# AT32M416xx_v2 register map
Vendor: Keil; Series: AT32M416; File version: 1.0
CPU: CM4 r0p1, little endian, no MPU, FPU, 4 interrupt priority bits
Registers are 32-bit, read-write, reset 0x0 unless marked. A register's access mark holds for its fields unless they carry their own. Offsets are from the block's base; [hi:lo] are bit positions.

## DAC — Digital to analog converter
Base 0x40007400
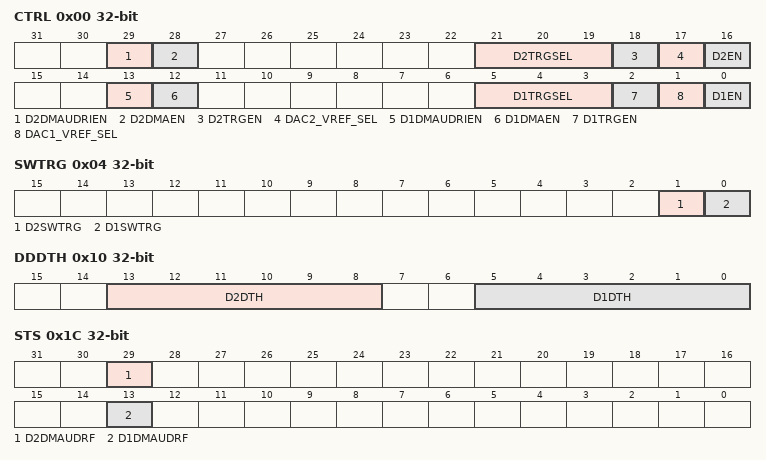
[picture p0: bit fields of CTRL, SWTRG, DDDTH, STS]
0x00 CTRL — Control register (DAC_CTRL)
  [29] D2DMAUDRIEN — DAC2 DMA underrun interrupt enable
  [28] D2DMAEN — DAC2 DMA enable
  [21:19] D2TRGSEL — DAC2 trigger selection
  [18] D2TRGEN — DAC2 trigger enable
  [17] DAC2_VREF_SEL — DAC2 reference voltage switch
  [16] D2EN — DAC2 enable
  [13] D1DMAUDRIEN — DAC1 DMA underrun interrupt enable
  [12] D1DMAEN — DAC1 DMA enable
  [5:3] D1TRGSEL — DAC1 trigger selection
  [2] D1TRGEN — DAC1 trigger enable
  [1] DAC1_VREF_SEL — DAC1 reference voltage switch
  [0] D1EN — DAC1 enable
0x04 SWTRG wo — DAC software trigger register(DAC_SWTRIGR)
  [1] D2SWTRG — DAC2 software trigger
  [0] D1SWTRG — DAC1 software trigger
0x08 D1DTH — DAC1 6-bit right-aligned data holding register(DAC_D1DTH)
  [5:0] D1DTH — DAC1 6-bit right-aligned data
0x0C D2DTH — DAC2 6-bit right aligned data holding register (DAC_D2DTH)
  [5:0] D2DTH — DAC2 6-bit right-aligned data
0x10 DDDTH — Dual DAC 6-bit right-aligned data holding register (DAC_DDDTH), Bits 31:14 Reserved, Bits 7:6 Reserved
  [13:8] D2DTH — DAC2 6-bit right-aligned data
  [5:0] D1DTH — DAC1 6-bit right-aligned data
0x14 D1ODT ro — DAC1 data output register (DAC_D1ODT)
  [5:0] D1ODT — DAC1 data output
0x18 D2ODT ro — DAC2 data output register (DAC_D2ODT)
  [5:0] D2ODT — DAC2 data output
0x1C STS — DAC status register(DAC_STS)
  [29] D2DMAUDRF — DAC2 DMA underrun flag
  [13] D1DMAUDRF — DAC1 DMA underrun flag
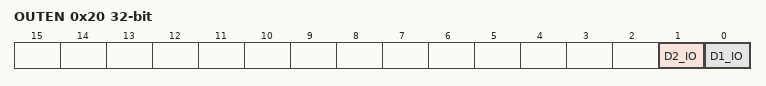
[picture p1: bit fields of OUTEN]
0x20 OUTEN — DAC output enable register(DAC_OUTEN)
  [1] D2_IO — DAC2 output to GPIO
  [0] D1_IO — DAC1 output to GPIO

## CMP — Comparator
Base 0x40013830
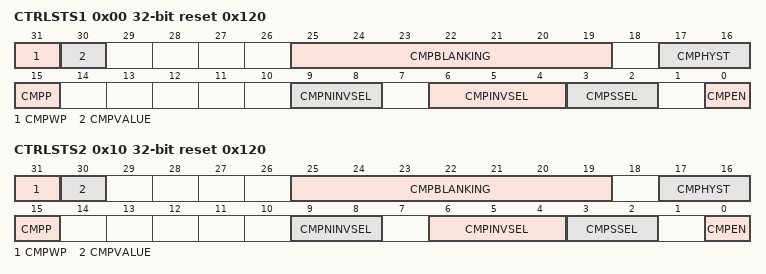
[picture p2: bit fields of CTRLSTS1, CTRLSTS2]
0x00 CTRLSTS1 reset 0x120 — CMP1 control and status register (CMP1_CTRLSTS)
  [31] CMPWP — Comparator write protect
  [30] CMPVALUE — Comparator 1 output value
  [25:19] CMPBLANKING — Comparator blank source
  [17:16] CMPHYST — Comparator hysteresis
  [15] CMPP — Comparator polarity
  [9:8] CMPNINVSEL — Comparator non-inverting selection
  [6:4] CMPINVSEL — Comparator inverting selection
  [3:2] CMPSSEL — Comparator speed selection
  [0] CMPEN — Comparator enable
0x04 G_FILTER_EN_1 — CMP1 glitch filter enable (CMP1_G_FILTER_EN)
  [0] GFE — Glitch filter enable
0x08 HIGH_PULSE_1 — CMP1 high pulse filter count (CMP1_HIGH_PULSE)
  [5:0] H_PULSE_CNT — High pulse count
0x0C LOW_PULSE_1 — CMP1 low pulse filter count
  [5:0] L_PULSE_CNT — Low pulse count
0x10 CTRLSTS2 reset 0x120 — CMP2 control and status register (CMP2_CTRLSTS)
  [31] CMPWP — Comparator write protect
  [30] CMPVALUE — Comparator 2 output value
  [25:19] CMPBLANKING — Comparator blank source
  [17:16] CMPHYST — Comparator hysteresis
  [15] CMPP — Comparator polarity
  [9:8] CMPNINVSEL — Comparator non-inverting selection
  [6:4] CMPINVSEL — Comparator inverting selection
  [3:2] CMPSSEL — Comparator speed selection
  [0] CMPEN — Comparator enable
0x14 G_FILTER_EN_2 — CMP2 glitch filter enable (CMP2_G_FILTER_EN)
  [0] GFE — Glitch filter enable
0x18 HIGH_PULSE_2 — CMP2 high pulse filter count (CMP2_HIGH_PULSE)
  [5:0] H_PULSE_CNT — High pulse count
0x1C LOW_PULSE_2 — CMP2 low pulse filter count (CMP2_LOW_PULSE)
  [5:0] L_PULSE_CNT — Low pulse count

## DEBUG — Debug support
Base 0xE0042000
0x00 IDCODE ro — DEBUG IDCODE
  [31:0] PID — Product ID
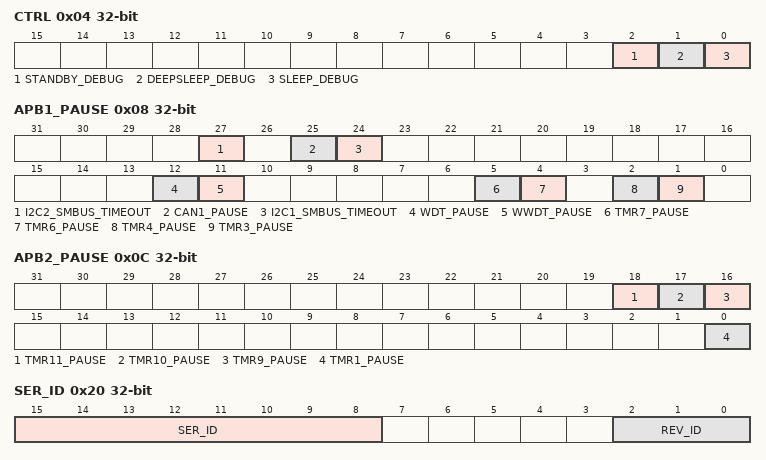
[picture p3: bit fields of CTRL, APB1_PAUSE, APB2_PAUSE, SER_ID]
0x04 CTRL — DEBUG CTRL
  [2] STANDBY_DEBUG, [1] DEEPSLEEP_DEBUG, [0] SLEEP_DEBUG
0x08 APB1_PAUSE — DEBUG APB1 PAUSE
  [27] I2C2_SMBUS_TIMEOUT, [25] CAN1_PAUSE, [24] I2C1_SMBUS_TIMEOUT, [12] WDT_PAUSE, [11] WWDT_PAUSE, [5] TMR7_PAUSE, [4] TMR6_PAUSE, [2] TMR4_PAUSE, [1] TMR3_PAUSE
0x0C APB2_PAUSE — DEBUG APB2 PAUSE
  [18] TMR11_PAUSE, [17] TMR10_PAUSE, [16] TMR9_PAUSE, [0] TMR1_PAUSE
0x10 APB3_PAUSE — DEBUG APB3 PAUSE
  [0] ERTC_PAUSE
0x20 SER_ID ro — SERIES ID
  [15:8] SER_ID — series ID
  [2:0] REV_ID — version ID
